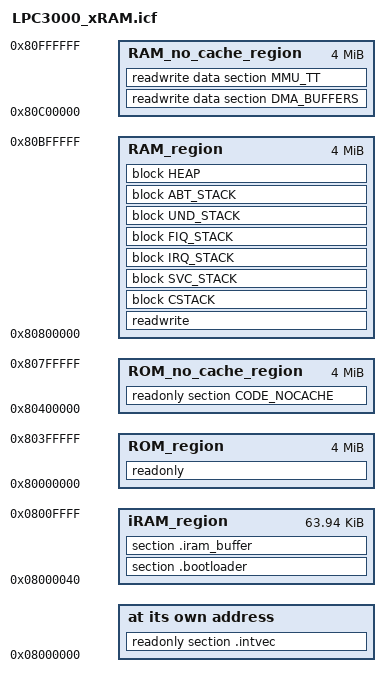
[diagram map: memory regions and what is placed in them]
/*###ICF### Section handled by ICF editor, don't touch! ****/
/*-Editor annotation file-*/
/* IcfEditorFile="$TOOLKIT_DIR$\config\ide\IcfEditor\a_v1_0.xml" */
/*-Specials-*/
define symbol __ICFEDIT_intvec_start__ = 0x08000000;
/*-Memory Regions-*/
define symbol __ICFEDIT_region_ROM_start__          = 0x80000000;
define symbol __ICFEDIT_region_ROM_end__            = 0x803FFFFF;
define symbol __ICFEDIT_region_RAM_start__          = 0x80800000;
define symbol __ICFEDIT_region_RAM_end__            = 0x80BFFFFF;
/*-Sizes-*/
define symbol __ICFEDIT_size_cstack__   = 0x1000;
define symbol __ICFEDIT_size_svcstack__ = 0x40;
define symbol __ICFEDIT_size_irqstack__ = 0x100;
define symbol __ICFEDIT_size_fiqstack__ = 0x40;
define symbol __ICFEDIT_size_undstack__ = 0x40;
define symbol __ICFEDIT_size_abtstack__ = 0x40;
define symbol __ICFEDIT_size_heap__     = 0x1000;
/**** End of ICF editor section. ###ICF###*/

define memory mem with size = 4G;
define region ROM_region          = mem:[from __ICFEDIT_region_ROM_start__  to __ICFEDIT_region_ROM_end__];

define symbol __region_ROM_no_cache_start__ = 0x80400000;
define symbol __region_ROM_no_cache_end__   = 0x807FFFFF;
define region ROM_no_cache_region = mem:[from __region_ROM_no_cache_start__ to __region_ROM_no_cache_end__];

define region RAM_region          = mem:[from __ICFEDIT_region_RAM_start__  to __ICFEDIT_region_RAM_end__];

define symbol __region_RAM_no_cache_start__ = 0x80C00000;
define symbol __region_RAM_no_cache_end__   = 0x80FFFFFF;
define region RAM_no_cache_region = mem:[from __region_RAM_no_cache_start__ to __region_RAM_no_cache_end__];

define symbol __region_iRAM_start__         = 0x08000040;
define symbol __region_iRAM_end__           = 0x0800FFFF;
define region iRAM_region         = mem:[from __region_iRAM_start__         to __region_iRAM_end__];

define block CSTACK    with alignment = 8, size = __ICFEDIT_size_cstack__   { };
define block SVC_STACK with alignment = 8, size = __ICFEDIT_size_svcstack__ { };
define block IRQ_STACK with alignment = 8, size = __ICFEDIT_size_irqstack__ { };
define block FIQ_STACK with alignment = 8, size = __ICFEDIT_size_fiqstack__ { };
define block UND_STACK with alignment = 8, size = __ICFEDIT_size_undstack__ { };
define block ABT_STACK with alignment = 8, size = __ICFEDIT_size_abtstack__ { };
define block HEAP      with alignment = 8, size = __ICFEDIT_size_heap__     { };

initialize by copy { readwrite };
do not initialize  { section .noinit };
do not initialize  { section MMU_TT };

place at address mem:__ICFEDIT_intvec_start__ { readonly section .intvec };

place in ROM_region   { readonly };

place in ROM_no_cache_region
                      { readonly section CODE_NOCACHE};

place in RAM_region   { readwrite,
                        block CSTACK, block SVC_STACK, block IRQ_STACK, block FIQ_STACK,
                        block UND_STACK, block ABT_STACK, block HEAP};

place in RAM_no_cache_region
                      { readwrite data section DMA_BUFFERS, readwrite data section MMU_TT };

place in iRAM_region  {section .bootloader };
place in iRAM_region  {section .iram_buffer};
